# nrf54h20_enga_application register map
Vendor: Nordic Semiconductor; Series: nRF54h; File version: 1
CPU: CM33 r0p4, little endian, MPU, FPU, 3 interrupt priority bits, 480 interrupts, 4 SAU regions
Registers are 32-bit, read-write, reset 0x0 unless marked. A register's access mark holds for its fields unless they carry their own. Offsets are from the block's base; [hi:lo] are bit positions; {n}, {i} and the like mark numbered series; 'fields as' and 'values as' point back to an identical list.

## GLOBAL_ETR_NS — Embedded Trace Router
Base 0xBF045000
0x04 RSZ — RAM Size register
  [30:0] RSZ — Size of the RAM in 32-bit words.
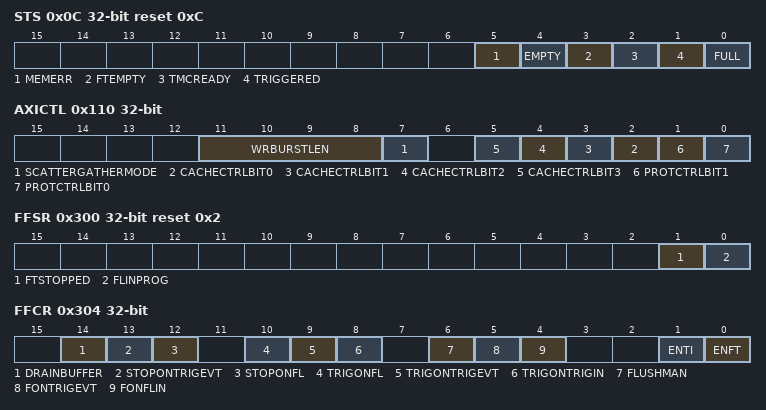
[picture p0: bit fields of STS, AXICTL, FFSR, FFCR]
0x0C STS ro reset 0xC — Status Register
  [5] MEMERR — This bit indicates that an error has occurred on the AXI master interface.
  [4] EMPTY — If set, this bit indicates that the TMC does not contain any valid trace data in the trace memory.
  [3] FTEMPTY — This bit is set when trace capture has stopped, and all internal pipelines and buffers have drained.
  [2] TMCREADY
  [1] TRIGGERED — The Triggered bit is set when trace capture is in progress and the TMC has detected a trigger event.
  [0] FULL — This bit can be used to help determine how much of the trace buffer contains valid data.
0x10 RRD ro — RAM Read Data Register
  [31:0] RRD — Reads return data from Trace RAM
0x14 RRP — RAM Read Pointer Register
  [8:0] RRP — This value represents the location in trace memory that will be accessed on a subsequent RRD read.
0x18 RWP — RAM Write Pointer Register
  [31:0] RWP — This value represents the location in trace memory that will be accessed on a subsequent write to the trace memory.
0x1C TRG — Trigger Counter Register
  [31:0] TRG — This count represents the number of 32-bit words between a TRIGIN/trigger packet and a trigger event.
0x20 CTL — Control Register
  [0] TRACECAPTEN — Setting this bit to 1 enables the TMC to capture trace data.
0x24 RWD wo — RAM Write Data Register
  [31:0] RWD — Data written to this register is placed in the Trace RAM.
0x28 MODE
  [1:0] MODE — Selects the operating mode.
    0=CIRCULARBUF (Circular Buffer mode); 1=FIFO (Software FIFO mode)
0x2C LBUFLEVEL ro — Latched Buffer Fill Level
  [30:0] LBUFLEVEL — Indicates the maximum fill level of the trace memory in 32-bit words since this register was last read.
0x30 CBUFLEVEL ro — Current Buffer Fill Level
  [7:0] CBUFLEVEL — Indicates the current fill level of the trace memory in 32-bit words.
0x34 BUFWM — Buffer Level Water Mark
  [6:0] BUFWM — Indicates the desired threshold vacancy level in 32-bit words in the trace memory.
0x38 RRPHI — RAM Read Pointer High Register
  [7:0] RRPHI — Bits[39:32] of the read pointer
0x3C RWPHI — RAM Write Pointer High Register
  [7:0] RWPHI — Bits[39:32] of the write pointer
0x110 AXICTL — AXI Control Register
  [11:8] WRBURSTLEN — This field indicates the maximum number of data transfers that can occur within each burst initiated by the TMC on the AXI interface.
  [7] SCATTERGATHERMODE — This bit indicates whether trace memory is accessed as a single buffer in system memory or as a linked-list based scatter-gather memory.
  [n+2] CACHECTRLBIT{n} (n=0..3) — This bit controls the value driven on the ARCACHEM[{n}]/AWCACHEM[{n}] signal on the AXI interface when performing AXI transfers.
  [1] PROTCTRLBIT1 — This bit controls the value driven on ARPROTM[1]/AWPROTM[1] on the AXI interface when performing AXI transfers.
  [0] PROTCTRLBIT0 — This bit controls the value driven on ARPROTM[0]/AWPROTM[0] on the AXI interface when performing AXI transfers.
0x118 DBALO — Data Buffer Address Low Register
  [31:0] BUFADDRLO — Holds the lower 32 bits of the 40-bit address used to locate the trace buffer in system memory
0x11C DBAHI — Data Buffer Address High Register
  [7:0] BUFADDRHI — Holds the upper 8 bits of the 40-bit address used to locate the trace buffer in system memory
0x300 FFSR ro reset 0x2 — Formatter and Flush Status Register
  [1] FTSTOPPED — This bit behaves the same way as the FtEmpty bit in the STS register, 0x00C.
  [0] FLINPROG — This bit indicates whether the TMC is currently processing a flush on the ATB slave port. This bit reflects the status of the AFVALIDS output. The flush initiation is controlled by the flush-control bits in the FFCR register.
0x304 FFCR — Formatter and Flush Control Register
  [14] DRAINBUFFER — This bit is used to enable draining of the trace data through the ATB Master interface after the formatter has stopped.
  [13] STOPONTRIGEVT — If this bit is set, the formatter is stopped when a Trigger Event has been observed.
  [12] STOPONFL — If this bit is set, the formatter is stopped on completion of a flush operation.
  [10] TRIGONFL — If this bit is set, a trigger is indicated on the trace stream on AFREADYS being returned.
  [9] TRIGONTRIGEVT — If this bit is set, a trigger is indicated on the output trace stream when a Trigger Event occurs.
  [8] TRIGONTRIGIN — If this bit is set, a trigger is indicated on the trace stream when a rising edge is detected on the TRIGIN input.
  [6] FLUSHMAN — Manually generate a flush of the system.
  [5] FONTRIGEVT — Setting this bit generates a flush when a Trigger event occurs.
  [4] FONFLIN — Setting this bit enables the detection of transitions on the FLUSHIN input by the TMC.
  [1] ENTI — Setting this bit enables the insertion of triggers in the formatted trace stream.
  [0] ENFT — If this bit is set, formatting is enabled.
0x308 PSCR — Periodic Synchronization Counter Register
  [4:0] PSCOUNT — The reload value of the Synchronization Counter
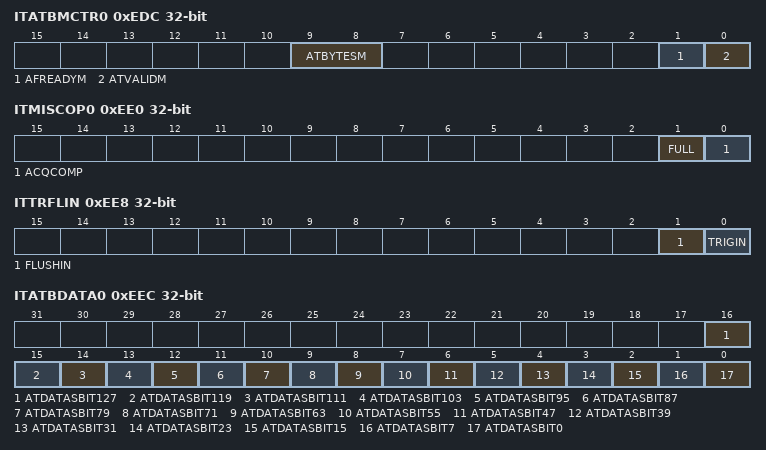
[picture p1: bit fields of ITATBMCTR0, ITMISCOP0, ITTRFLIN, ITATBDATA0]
0xEDC ITATBMCTR0 wo — Integration Test ATB Master Interface Control 0 Register
  [9:8] ATBYTESM — Control the value of ATBYTESM output from TMC. The value written to this field is driven on the ATBYTESM output of the TMC.
  [1] AFREADYM — Set the value of AFREADYM output
  [0] ATVALIDM — Set the value of ATVALIDM output
0xEE0 ITMISCOP0 wo — Integration Test Miscellaneous Output Register 0
  [1] FULL — Set the value of the FULL output.
  [0] ACQCOMP — Set the value of the ACQCOMP output.
0xEE8 ITTRFLIN ro — Integration Test Trigger In and Flush In Register
  [1] FLUSHIN — Read the value of the FLUSHIN input.
  [0] TRIGIN — Read the value of the TRIGIN input.
0xEEC ITATBDATA0 ro — Integration Test ATB Data Register 0
  [16] ATDATASBIT127 — Read the value of ATDATAS[127] input to TMC
  [15] ATDATASBIT119 — Read the value of ATDATAS[119] input to TMC
  [14] ATDATASBIT111 — Read the value of ATDATAS[111] input to TMC
  [13] ATDATASBIT103 — Read the value of ATDATAS[103] input to TMC
  [12] ATDATASBIT95 — Read the value of ATDATAS[95] input to TMC
  [11] ATDATASBIT87 — Read the value of ATDATAS[87] input to TMC
  [10] ATDATASBIT79 — Read the value of ATDATAS[79] input to TMC
  [9] ATDATASBIT71 — Read the value of ATDATAS[71] input to TMC
  [8] ATDATASBIT63 — Read the value of ATDATAS[63] input to TMC
  [7] ATDATASBIT55 — Read the value of ATDATAS[55] input to TMC
  [6] ATDATASBIT47 — Read the value of ATDATAS[47] input to TMC
  [5] ATDATASBIT39 — Read the value of ATDATAS[39] input to TMC
  [4] ATDATASBIT31 — Read the value of ATDATAS[31] input to TMC
  [3] ATDATASBIT23 — Read the value of ATDATAS[23] input to TMC
  [2] ATDATASBIT15 — Read the value of ATDATAS[15] input to TMC
  [1] ATDATASBIT7 — Read the value of ATDATAS[7] input to TMC
  [0] ATDATASBIT0 — Read the value of ATDATAS[0] input to TMC
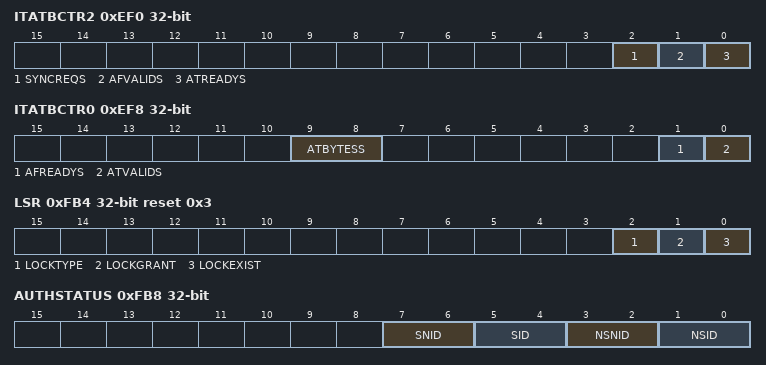
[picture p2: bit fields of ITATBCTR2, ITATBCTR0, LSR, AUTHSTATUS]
0xEF0 ITATBCTR2 wo — Integration Test ATB Control 2 Register
  [2] SYNCREQS — Set the value of SYNCREQS output
  [1] AFVALIDS — Set the value of AFVALIDS output
  [0] ATREADYS — Set the value of ATREADYS output
0xEF4 ITATBCTR1 ro — Integration Test ATB Control 1 Register
  [6:0] ATIDS — Read the value of ATIDS input to TMC
0xEF8 ITATBCTR0 ro — Integration Test ATB Control 0 Register
  [9:8] ATBYTESS — Read the value of ATBYTESS input to TMC
  [1] AFREADYS — Read the value of AFREADYS input to TMC
  [0] ATVALIDS — Read the value of ATVALIDS input to TMC
0xF00 ITCTRL — Integration Mode Control Register
  [0] INTEGRATION_MODE — Allows the component to switch from functional mode to integration mode or back.
0xFA0 CLAIMSET reset 0xF — Claim Tag Set Register
  [3:0] CLAIMSET — This claim tag bit is implemented
0xFA4 CLAIMCLR — Claim Tag Clear Register
  [3:0] CLAIMCLR — The value present reflects the current setting of the Claim Tag.
0xFB0 LAR wo — Lock Access Register
  [31:0] ACCESS_W — A write of 0xC5ACCE55 enables further write access to this device. A write of any value other than 0xC5ACCE55 will have the affect of removing write access.
0xFB4 LSR ro reset 0x3 — Lock Status Register
  [2] LOCKTYPE — Indicates if the Lock Access Register (0xFB0) is implemented as 8-bit or 32-bit
    0=32BIT (This component implements a 32-bit Lock Access Register)
  [1] LOCKGRANT — Returns the current status of the Lock.
  [0] LOCKEXIST — Indicates that a lock control mechanism exists for this device.
0xFB8 AUTHSTATUS ro — Authentication Status Register
  [7:6] SNID — Indicates the security level for secure non-invasive debug
    0=NONE (Functionality not implemented or controlled elsewhere.)
  [5:4] SID — Indicates the security level for secure invasive debug
    2=DISABLED (Functionality disabled. This return value occurs when DBGEN is LOW or SPIDEN is LOW.); 3=ENABLED (Functionality enabled. This return value occurs when DBGEN and SPIDEN are HIGH.)
  [3:2] NSNID — Indicates the security level for non-secure non-invasive debug
    values as SNID
  [1:0] NSID — Indicates the security level for non-secure invasive debug
    2=DISABLED (Functionality disabled. This return value occurs when DBGEN is LOW.); 3=ENABLED (Functionality enabled. This return value occurs when DBGEN is HIGH.)
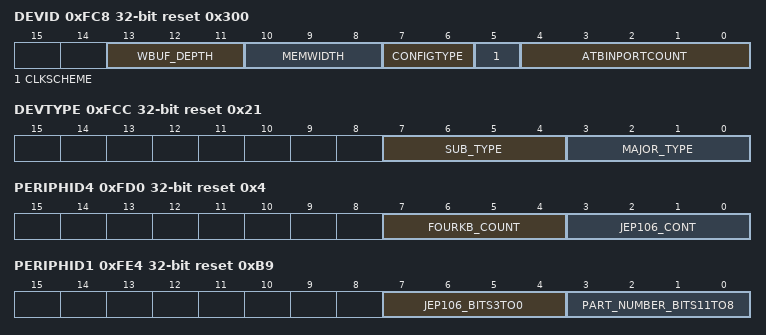
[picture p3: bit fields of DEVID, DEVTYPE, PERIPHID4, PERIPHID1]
0xFC8 DEVID ro reset 0x300 — Device Configuration Register
  [13:11] WBUF_DEPTH — This value indicates, in powers of two, the number of entries in the Write buffer. Each entry is of size ATB_DATA_WIDTH.
    2=4ENTRIES (Depth of the Write buffer is 4 entries.); 3=8ENTRIES (Depth of the Write buffer is 8 entries.); 4=16ENTRIES (Depth of the Write buffer is 16 entries.); 5=32ENTRIES (Depth of the Write buffer is 32 entries.)
  [10:8] MEMWIDTH — This value indicates the width of the Memory interface databus.
    2=32BIT (Memory interface databus is 32 bits wide.); 3=64BIT (Memory interface databus is 64 bits wide.); 4=128BIT (Memory interface databus is 128 bits wide.); 5=256BIT (Memory interface databus is 256 bits wide.)
  [7:6] CONFIGTYPE — This value indicates TMC configuration type.
    0=ETB (Unspecified); 1=ETR (Unspecified); 2=ETF (Unspecified)
  [5] CLKSCHEME — This value indicates the TMC RAM clocking scheme used, ie. whether the TMC RAM operates synchronously or asynchronously to CLK.
    0=SYNC (The TMC RAM operates synchronously to CLK.)
  [4:0] ATBINPORTCOUNT — This value indicates the type/number of ATB multiplexing present on the input ATB.
0xFCC DEVTYPE ro reset 0x21 — Device Type Identifier Register
  [7:4] SUB_TYPE — Sub-classification within the major category
    2=This component captures the trace data into RAM that can be drained through APB
  [3:0] MAJOR_TYPE — Major classification grouping for this debug/trace component
    1=SINK (This component is a trace sink.)
0xFD0 PERIPHID4 ro reset 0x4 — Peripheral ID4 Register
  [7:4] FOURKB_COUNT — This is a 4-bit value that indicates the total contiguous size of the memory window used by this component in powers of 2 from the standard 4KB. If a component only requires the standard 4KB then this should read as 0x0, 4KB only, for 8KB set to 0x1, 16KB == 0x2, 32KB == 0x3, and so on.
  [3:0] JEP106_CONT — JEDEC continuation code indicating the designer of the component (along with the identity code)
0xFE0 PERIPHID0 ro reset 0x61 — Peripheral ID0 Register
  [7:0] PART_NUMBER_BITS7TO0 — Bits [7:0] of the component's part number. This is selected by the designer of the component.
0xFE4 PERIPHID1 ro reset 0xB9 — Peripheral ID1 Register
  [7:4] JEP106_BITS3TO0 — Bits 3:0 of the JEDEC identity code indicating the designer of the component (along with the continuation code)
  [3:0] PART_NUMBER_BITS11TO8 — Bits [11:8] of the component's part number. This is selected by the designer of the component.
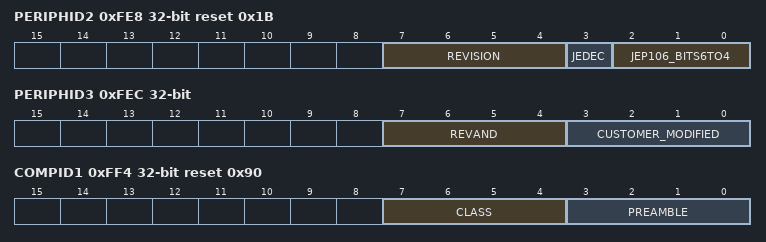
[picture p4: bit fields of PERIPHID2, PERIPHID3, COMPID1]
0xFE8 PERIPHID2 ro reset 0x1B — Peripheral ID2 Register
  [7:4] REVISION — The Revision field is an incremental value starting at 0x0 for the first design of this component. This only increases by 1 for both major and minor revisions and is simply used as a look-up to establish the exact major/minor revision.
  [3] JEDEC — Always set. Indicates that a JEDEC assigned value is used
  [2:0] JEP106_BITS6TO4 — Bits 6:4 of the JEDEC identity code indicating the designer of the component (along with the continuation code)
0xFEC PERIPHID3 ro — Peripheral ID3 Register
  [7:4] REVAND — This field indicates minor errata fixes specific to this design, for example metal fixes after implementation. In most cases this field is zero. It is recommended that component designers ensure this field can be changed by a metal fix if required, for example by driving it from registers that reset to zero.
  [3:0] CUSTOMER_MODIFIED — Where the component is reusable IP, this value indicates if the customer has modified the behavior of the component. In most cases this field is zero.
0xFF0 COMPID0 ro reset 0xD — Component ID0 Register
  [7:0] PREAMBLE — Contains bits [7:0] of the component identification
0xFF4 COMPID1 ro reset 0x90 — Component ID1 Register
  [7:4] CLASS — Class of the component. E.g. ROM table, CoreSight component etc. Constitutes bits [15:12] of the component identification.
  [3:0] PREAMBLE — Contains bits [11:8] of the component identification
0xFF8 COMPID2 ro reset 0x5 — Component ID2 Register
  [7:0] PREAMBLE — Contains bits [23:16] of the component identification
0xFFC COMPID3 ro reset 0xB1 — Component ID3 Register
  [7:0] PREAMBLE — Contains bits [31:24] of the component identification
